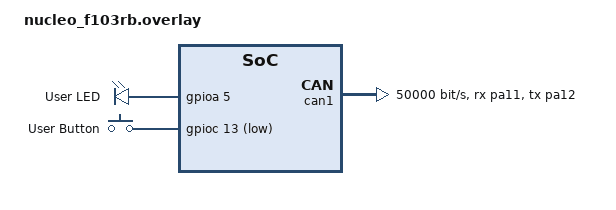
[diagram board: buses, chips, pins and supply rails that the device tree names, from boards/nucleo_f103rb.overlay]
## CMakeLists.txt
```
cmake_minimum_required(VERSION 3.20.0)

find_package(Zephyr REQUIRED HINTS $ENV{ZEPHYR_BASE})
project(antenna_app)

list(APPEND CMAKE_MODULE_PATH ${ZEPHYR_BASE}/modules/nanopb)
include(nanopb)

file(GLOB_RECURSE RADIOLIB_SOURCES
    ${CMAKE_CURRENT_SOURCE_DIR}/lib/RadioLib/src/*.cpp
)
list(FILTER RADIOLIB_SOURCES EXCLUDE REGEX ".*/hal/.*\\.cpp$")

target_sources(app PRIVATE
    src/main.cpp
    src/radio.cpp
    src/hal/radio_hal.cpp
    src/can_handler.cpp  # Add your CAN file here too
    src/metrics.cpp
    ${RADIOLIB_SOURCES}
)

target_include_directories(app PRIVATE
    ${CMAKE_CURRENT_SOURCE_DIR}/lib/RadioLib/src
    ${CMAKE_CURRENT_SOURCE_DIR}/src/hal
)

# 2. Add Nanopb sources. 
# Zephyr's Nanopb module provides this function automatically 
# if CONFIG_NANOPB=y is in your prj.conf.
zephyr_nanopb_sources(app src/dant_link.proto)
```

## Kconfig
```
mainmenu "DANT Application"

source "Kconfig.zephyr"

menu "DANT options"

choice DANT_NODE_ROLE
	prompt "DANT node role"
	default DANT_NODE_A

config DANT_NODE_A
	bool "Node A"

config DANT_NODE_B
	bool "Node B"

endchoice

config DANT_TX_PERIOD_MS
	int "TX period in milliseconds"
	default 1000
	range 10 60000

endmenu
```

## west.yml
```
manifest:
  remotes:
    - name: zephyrproject
      url-base: https://github.com/zephyrproject-rtos

  projects:
    - name: zephyr
      remote: zephyrproject
      revision: 3568e1b6d5cdd51a6b964a2a1d6d29200fea2056
      import:
        name-allowlist:
          - cmsis_6
          - hal_stm32
          - nanopb

  self:
    path: antenna_app
```

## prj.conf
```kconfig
# Kernel
CONFIG_MAIN_STACK_SIZE=2048
CONFIG_HEAP_MEM_POOL_SIZE=2048
CONFIG_REBOOT=y

# Console
CONFIG_SERIAL=y
CONFIG_CONSOLE=y
CONFIG_PRINTK=y

# GPIO
CONFIG_GPIO=y
# This enables the specific STM32F1xx HAL driver files

# SPI
CONFIG_SPI=y

# CAN
CONFIG_CAN=y
## STM32 requires specific clock settings for CAN, usually handled by Zephyr
CONFIG_STATS=y
CONFIG_CAN_STATS=y

# Debugger
CONFIG_DEBUG=y
CONFIG_DEBUG_OPTIMIZATIONS=y

# Logger
CONFIG_LOG=y
CONFIG_LOG_DEFAULT_LEVEL=3

# C++
CONFIG_CPP=y

CONFIG_STDOUT_CONSOLE=y
CONFIG_UART_CONSOLE=y

# Enable protobuf
CONFIG_NANOPB=y
```

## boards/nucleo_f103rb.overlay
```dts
/ {
    chosen {
        /* Links the CAN driver to your code's DEVICE_DT_GET(DT_CHOSEN(zephyr_canbus)) */
        zephyr,canbus = &can1;
    };

    /* Most STM32F103 boards already have 'led0' defined in the base DTS,
       but we ensure the alias is set here for the blinky code. */
    aliases {
        led0 = &green_led_1;
		/* Define the sw0 alias so your code can find the button */
        sw0 = &user_button_1;
    };

    leds {
        compatible = "gpio-leds";
        green_led_1: led_1 {
            gpios = <&gpioa 5 GPIO_ACTIVE_HIGH>;
            label = "User LED";
        };
    };

	/* Add the buttons node here */
    buttons {
        compatible = "gpio-keys";
        user_button_1: button_1 {
            /* PC13 is the standard B1 button on the Nucleo-F103RB */
            gpios = <&gpioc 13 GPIO_ACTIVE_LOW>;
            label = "User Button";
        };
    };
};

/* CAN configuration */
&can1 {
    status = "okay";
    pinctrl-0 = <&can_rx_pa11 &can_tx_pa12>;
    pinctrl-names = "default";
    bitrate = <50000>;
    sample-point = <750>;

    /* Optional: If you have a transceiver with a standby pin */
    /* standby-gpios = <&gpiob 0 GPIO_ACTIVE_HIGH>; */
};
```

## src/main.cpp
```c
#include <zephyr/kernel.h>
#include <zephyr/sys/printk.h>
#include <zephyr/drivers/gpio.h>
#include <zephyr/logging/log.h>
#include <zephyr/sys/reboot.h>
//#include <state_system.h>
#include <RadioLib.h>
#include <STMRadioHal.h>
#include <zephyr/drivers/spi.h>
#include <string.h>
#include "radio.h"


#define SPI_DEV    DT_NODELABEL(spi1)
#define GPIO_NODE  DT_NODELABEL(gpioa)
#define GPIO_CS_NODE DT_NODELABEL(gpioa)
#define CS_PIN     4
#define IRQ_PIN    8
#define RST_PIN    9
#define BUSY_PIN   10
#define RADIO_TASK_STACK_SIZE 4096
#define RADIO_TASK_PRIORITY 5

enum class State {
    BOOT,
    WAKE,
    DEPLOYING,
    VITALS,
    REGULAR,
    FAULT,
    RESTART,
    SAFE,
    RADIO_TEST
};

LOG_MODULE_REGISTER(radio_task, CONFIG_LOG_DEFAULT_LEVEL);

const struct device *const spi_bus = DEVICE_DT_GET(SPI_DEV);
const struct device *const gpio_port = DEVICE_DT_GET(GPIO_NODE);
const struct device *const gpio_cs_port = DEVICE_DT_GET(GPIO_CS_NODE);


K_THREAD_STACK_DEFINE(radio_task_stack, RADIO_TASK_STACK_SIZE);
//static struct k_thread radio_task_thread;
static bool radio_thread_started = false;

volatile bool tx_done = false;
State currentState = State::BOOT;

void onTxDone(void)
{
    tx_done = true;
}

static void radio_queue_entry(void *p1, void *p2, void *p3)
{
    ARG_UNUSED(p1);
    ARG_UNUSED(p2);
    ARG_UNUSED(p3);
    radio_task_cpp();
}

/*
static bool start_radio_thread_once(void)
{
    if (radio_thread_started) {
        return true;
    }

    k_thread_create(
        &radio_task_thread,
        radio_task_stack,
        K_THREAD_STACK_SIZEOF(radio_task_stack),
        radio_queue_entry,
        NULL,
        NULL,
        NULL,
        RADIO_TASK_PRIORITY,
        0,
        K_NO_WAIT);

    radio_thread_started = true;
    return true;
}
*/
int main(void)
{
    while (1) {
        if(fault_take){//execute when it fault_take() return true
            LOG_ERR("Fault flag: FAULT");
            currentState = State :: FAULT; //set the state to FAULT
        }
        switch (currentState) {
        case State::BOOT: {
            bool ready = true;

            if (!check_spi(spi_bus)) {
                LOG_ERR("SPI bus not ready");
                ready = false;
            }

            if (!check_gpio(gpio_port)) {
                check_gpio();
                LOG_ERR("GPIO port not ready");
                ready = false;
            }

            if (!check_gpio_cs(gpio_cs_port)) {
                LOG_ERR("GPIO CS port not ready");
                ready = false;
            }

            if (!ready) {
                currentState = State::FAULT;
                break;
            }

            if (check_init_radio() != 0) {
                LOG_ERR("Radio init failed");
                currentState = State::FAULT;
                break;
            }

            if (!start_radio_thread_once()) {
                LOG_ERR("Radio thread start failed");
                currentState = State::FAULT;
                break;
            }

            currentState = State::WAKE;
            break;
        }

        case State::WAKE:
            LOG_INF("State: WAKE");
            currentState = State::VITALS;
            break;

        case State::DEPLOYING:
            LOG_INF("State: DEPLOYING");
            currentState = State::REGULAR;
            break;

        case State::VITALS:
            LOG_INF("State: VITALS");
            currentState = State::REGULAR;
            break;

        case State::REGULAR:
            // Normal operations placeholder.
            k_msleep(100);
            break;

        case State::SAFE:
            LOG_WRN("State: SAFE");
            k_msleep(250);
            break;

        case State::RADIO_TEST:
            LOG_INF("State: RADIO_TEST");
            radio_test();
            currentState = State::REGULAR;
            break;

        case State::FAULT:
            LOG_ERR("State: FAULT");
            currentState = State::RESTART;
            break;

        case State::RESTART:
            LOG_WRN("State: RESTART");
            k_msleep(100);
            sys_reboot(SYS_REBOOT_COLD); // this is powering off and restarting, not just rebooting
            break;
        }
    }

    return 0;
}
```

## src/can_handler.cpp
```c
#include <zephyr/device.h>
#include <zephyr/drivers/can.h>
#include <zephyr/kernel.h>
#include <zephyr/sys/printk.h>

CAN_MSGQ_DEFINE(can_rx_queue, 4);

static void print_can_state(const struct device *dev)
{
    enum can_state state;
    struct can_bus_err_cnt errors;
    const int ret = can_get_state(dev, &state, &errors);

    if (ret == 0) {
        printk("CAN state=%d tx_errors=%u rx_errors=%u\n",
               (int)state, errors.tx_err_cnt, errors.rx_err_cnt);
    }
}

static void can_task_entry(void *arg1, void *arg2, void *arg3)
{
    ARG_UNUSED(arg1);
    ARG_UNUSED(arg2);
    ARG_UNUSED(arg3);

    const struct device *const can_dev =
        DEVICE_DT_GET(DT_CHOSEN(zephyr_canbus));

    if (!device_is_ready(can_dev)) {
        printk("CAN device is not ready\n");
        return;
    }

    int ret = can_set_mode(can_dev, CAN_MODE_NORMAL);
    if (ret != 0) {
        printk("CAN mode failed: %d\n", ret);
        return;
    }

    const struct can_filter filter = {
        .id = 0x123,
        .mask = CAN_STD_ID_MASK,
        .flags = 0U,
    };
    const int filter_id = can_add_rx_filter_msgq(
        can_dev, &can_rx_queue, &filter);
    if (filter_id < 0) {
        printk("CAN filter registration failed: %d\n", filter_id);
        return;
    }

    printk("Node %s: RX filter installed for ID 0x123\n",
           IS_ENABLED(CONFIG_DANT_NODE_A) ? "A" : "B");

    ret = can_start(can_dev);
    if (ret != 0) {
        printk("CAN start failed: %d\n", ret);
        return;
    }

    printk("CAN started\n");

    struct can_frame frame = {};

    if (IS_ENABLED(CONFIG_DANT_NODE_A)) {
        frame.id = 0x123;
        frame.dlc = 1;
        frame.data[0] = 42;

        while (true) {
            printk("CAN task alive\n");
            ret = can_send(can_dev, &frame, K_MSEC(100), nullptr, nullptr);
            if (ret != 0) {
                printk("CAN send failed: %d\n", ret);
                print_can_state(can_dev);
            } else {
                printk("CAN frame sent\n");
            }
            k_msleep(1000);
        }
    } else {
        while (true) {
            ret = k_msgq_get(&can_rx_queue, &frame, K_FOREVER);
            if (ret == 0 && frame.dlc >= 1U &&
                (frame.flags & CAN_FRAME_RTR) == 0U) {
                printk("Received ID: 0x%x, data: %u\n",
                       (unsigned int)frame.id,
                       (unsigned int)frame.data[0]);
            }
        }
    }
}

K_THREAD_DEFINE(can_task_id, 1024, can_task_entry,
                nullptr, nullptr, nullptr,
                5, 0, 0);
```

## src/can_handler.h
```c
#ifndef CAN_HANDLER_H
#define CAN_HANDLER_H

#include <zephyr/types.h>

#ifdef __cplusplus
/* Add this so main.cpp can see the semaphore */
extern struct k_sem blink_sem;
extern "C" {
#endif

/**
 * @brief Initializes the CAN controller and GPIO LED.
 * * Sets up the default RX filter to accept all standard data frames,
 * configures the onboard LED for activity toggling, and starts the
 * CAN peripheral.
 *
 * @retval 0 if successful.
 * @retval -ENODEV if hardware devices are not ready.
 * @retval Negative errno code from zephyr CAN API on failure.
 */
int can_handler_init(void);

/**
 * @brief Transmits a classic CAN frame.
 *
 * @param id   The CAN ID (Standard).
 * @param data Pointer to the data buffer (max 8 bytes).
 * @param len  Length of data to send (clipped to 8).
 *
 * @retval 0 if successful.
 * @retval Negative errno code (e.g., -EAGAIN, -ENETDOWN) on failure.
 */
int can_handler_send(uint32_t id, uint8_t *data, uint8_t len);

#ifdef __cplusplus
}
#endif

#endif /* CAN_HANDLER_H */
```

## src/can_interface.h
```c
#pragma once

#include "can_link.h"
#include <cstddef>
#include <cstdint>

using CanReceiveCallback = can_link_rx_handler_t;

inline int can_interface_init(
    CanReceiveCallback callback,
    void* user_data = nullptr)
{
    return can_link_init(callback, user_data);
}

// Returns 0 when the transfer starts, not when delivery completes.
// Returns -EBUSY if another transfer is already active.
inline int can_interface_send_to(
    std::uint8_t target_node,
    const std::uint8_t* payload,
    std::size_t length)
{
    return can_link_send_to(target_node, payload, length);
}

// The current SDSL-CAN implementation limits broadcasts to 7 bytes.
inline int can_interface_send_broadcast(
    const std::uint8_t* payload,
    std::size_t length)
{
    return can_link_send_broadcast(payload, length);
}
```

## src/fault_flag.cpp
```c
#include "fault_flag.h"

static volatile bool pending = false;

void fault_request(){
    pending = true;
}

bool fault_take(){
    if(!pending){
        return false;
    }
    pending = false;
    return true;

}
```

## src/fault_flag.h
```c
#pragma once

void fault_request(void);
bool fault_take(void);
```

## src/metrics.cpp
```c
/**
 * @file metrics.cpp
 * @brief Metrics counter storage and update routines.
 *
 * Runtime counters are stored as Zephyr atomics so they can be updated from
 * the main thread, radio task, or callback paths. The boot counter is mirrored
 * in RAM but persisted through the Zephyr Settings API using the NVS backend.
 */

#include "metrics.h"

#include <errno.h>
#include <stddef.h>
#include <sys/types.h>
#include <zephyr/settings/settings.h>
#include <zephyr/sys/atomic.h>

#define METRICS_BOOT_COUNT_KEY "metrics/boot_count"

static atomic_t boot_count;
static atomic_t fault_count;
static atomic_t radio_tx_attempts;
static atomic_t radio_tx_successes;
static atomic_t radio_tx_failures;
static atomic_t radio_retries;
static atomic_t radio_queue_full_count;
static atomic_t successful_cycles;

static bool persistent_metrics_ready;

/**
 * @brief Convert a Zephyr atomic counter to the public 32-bit metric type.
 *
 * @param counter Atomic counter to read.
 * @return Current counter value.
 */
static uint32_t metrics_counter_get(const atomic_t *counter)
{
    return (uint32_t)atomic_get(counter);
}

/**
 * @brief Load the persisted boot count from Settings/NVS.
 *
 * A missing key is treated as a first boot and returns zero.
 *
 * @param value Output location for the loaded boot count.
 * @retval 0 if a value was loaded or the key did not exist.
 * @retval -EINVAL if the stored value length is unexpected.
 * @retval negative Zephyr error code from settings_load_one().
 */
static int metrics_load_boot_count(uint32_t *value)
{
    ssize_t ret = settings_load_one(METRICS_BOOT_COUNT_KEY, value, sizeof(*value));

    if (ret == -ENOENT) {
        *value = 0U;
        return 0;
    }

    if (ret < 0) {
        return (int)ret;
    }

    return ret == sizeof(*value) ? 0 : -EINVAL;
}

/**
 * @brief Persist a boot count value to Settings/NVS.
 *
 * @param value Boot count to save.
 * @retval 0 on success.
 * @retval negative Zephyr error code from settings_save_one().
 */
static int metrics_save_boot_count(uint32_t value)
{
    return settings_save_one(METRICS_BOOT_COUNT_KEY, &value, sizeof(value));
}

void metrics_init(void)
{
    uint32_t stored_boot_count = 0U;
    int ret = settings_subsys_init();

    if (ret != 0) {
        persistent_metrics_ready = false;
        atomic_inc(&fault_count);
        return;
    }

    persistent_metrics_ready = true;

    ret = metrics_load_boot_count(&stored_boot_count);
    if (ret != 0) {
        atomic_inc(&fault_count);
        return;
    }

    atomic_set(&boot_count, (atomic_val_t)stored_boot_count);
}

void metrics_inc_boot(void)
{
    uint32_t value = (uint32_t)atomic_inc(&boot_count) + 1U;

    if (persistent_metrics_ready && metrics_save_boot_count(value) != 0) {
        atomic_inc(&fault_count);
    }
}

int metrics_reset_boot_count(void)
{
    uint32_t value = 0U;

    if (!persistent_metrics_ready) {
        return -EIO;
    }

    int ret = metrics_save_boot_count(value);
    if (ret != 0) {
        return ret;
    }

    atomic_set(&boot_count, (atomic_val_t)value);
    return 0;
}

void metrics_inc_fault(void)
{
    atomic_inc(&fault_count);
}

void metrics_inc_radio_tx_attempt(void)
{
    atomic_inc(&radio_tx_attempts);
}

void metrics_inc_radio_tx_success(void)
{
    atomic_inc(&radio_tx_successes);
}

void metrics_inc_radio_tx_failure(void)
{
    atomic_inc(&radio_tx_failures);
}

void metrics_inc_radio_retry(void)
{
    atomic_inc(&radio_retries);
}

void metrics_inc_radio_queue_full(void)
{
    atomic_inc(&radio_queue_full_count);
}

void metrics_inc_successful_cycle(void)
{
    atomic_inc(&successful_cycles);
}

struct metrics_snapshot metrics_get_snapshot(void)
{
    struct metrics_snapshot snapshot = {};

    snapshot.boot_count = metrics_counter_get(&boot_count);
    snapshot.fault_count = metrics_counter_get(&fault_count);
    snapshot.radio_tx_attempts = metrics_counter_get(&radio_tx_attempts);
    snapshot.radio_tx_successes = metrics_counter_get(&radio_tx_successes);
    snapshot.radio_tx_failures = metrics_counter_get(&radio_tx_failures);
    snapshot.radio_retries = metrics_counter_get(&radio_retries);
    snapshot.radio_queue_full_count = metrics_counter_get(&radio_queue_full_count);
    snapshot.successful_cycles = metrics_counter_get(&successful_cycles);

    return snapshot;
}
```

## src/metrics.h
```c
/**
 * @file metrics.h
 * @brief Runtime and persistent health metrics for the antenna application.
 *
 * The metrics module tracks core health counters that can be sampled by
 * telemetry, debug commands, or future CAN/protobuf status messages. Most
 * counters are runtime-only atomics. The boot counter is backed by Zephyr
 * Settings/NVS so it survives reboot and power loss.
 */

#ifndef METRICS_H
#define METRICS_H

#include <stdint.h>

#ifdef __cplusplus
extern "C" {
#endif

/**
 * @brief Snapshot of all metrics counters.
 *
 * A snapshot is a point-in-time copy. It does not lock future updates, so use
 * it as telemetry/debug state rather than as a transactional record.
 */
struct metrics_snapshot {
    /** Number of completed boot-count increments persisted in Settings/NVS. */
    uint32_t boot_count;
    /** Count of recoverable fault/error paths observed since this boot. */
    uint32_t fault_count;
    /** Number of radio transmit operations attempted since this boot. */
    uint32_t radio_tx_attempts;
    /** Number of radio transmit operations that completed successfully. */
    uint32_t radio_tx_successes;
    /** Number of radio transmit operations that failed after retries. */
    uint32_t radio_tx_failures;
    /** Number of additional radio transmit attempts after first failure. */
    uint32_t radio_retries;
    /** Number of radio queue insertions rejected because the queue was full. */
    uint32_t radio_queue_full_count;
    /** Number of application cycles that reached a successful TX completion. */
    uint32_t successful_cycles;
};

/**
 * @brief Initialize metrics storage and load persistent counters.
 *
 * This initializes the Zephyr Settings backend and loads the persisted
 * `boot_count`. If persistent storage cannot be initialized or read, the
 * module keeps running with runtime counters and records a fault.
 */
void metrics_init(void);

/**
 * @brief Increment and persist the boot counter.
 *
 * Call once during application startup after metrics_init(). The saved value is
 * updated immediately so the count survives a later reset or power loss.
 */
void metrics_inc_boot(void);

/**
 * @brief Reset the persistent and in-memory boot count to zero.
 *
 * The next startup call to metrics_inc_boot() will report boot_count == 1.
 *
 * @retval 0 if the reset was saved and applied.
 * @retval -EIO if persistent metrics storage is not ready.
 * @retval negative Zephyr error code if Settings/NVS could not save the value.
 */
int metrics_reset_boot_count(void);

/** @brief Increment the recoverable fault counter. */
void metrics_inc_fault(void);

/** @brief Increment the radio transmit attempt counter. */
void metrics_inc_radio_tx_attempt(void);

/** @brief Increment the radio transmit success counter. */
void metrics_inc_radio_tx_success(void);

/** @brief Increment the radio transmit failure counter. */
void metrics_inc_radio_tx_failure(void);

/** @brief Increment the radio retry counter. */
void metrics_inc_radio_retry(void);

/** @brief Increment the radio queue-full counter. */
void metrics_inc_radio_queue_full(void);

/** @brief Increment the successful application cycle counter. */
void metrics_inc_successful_cycle(void);

/**
 * @brief Return a point-in-time copy of all metrics counters.
 *
 * @return Snapshot containing persistent boot count and runtime counters.
 */
struct metrics_snapshot metrics_get_snapshot(void);

#ifdef __cplusplus
}
#endif

#endif /* METRICS_H */
```

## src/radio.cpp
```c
#include "radio.h"
#include "hal/STMRadioHal.h"
#include <zephyr/drivers/gpio.h>
#include <zephyr/drivers/spi.h>
#include <zephyr/logging/log.h>
#include <string.h>

LOG_MODULE_REGISTER(radio, CONFIG_LOG_DEFAULT_LEVEL);

extern "C" __attribute__((weak)) void telemetry_send_radio_stats(int16_t rssi, int8_t snr, uint8_t radio) {
    ARG_UNUSED(rssi);
    ARG_UNUSED(snr);
    ARG_UNUSED(radio);
}

// Radio instances
static Module* module_sx = nullptr;
static Module* module_rfm = nullptr;
static SX1268* radio_sx = nullptr;
static RFM98* radio_rfm = nullptr;
static STMRadioHal* hal_sx = nullptr;
static STMRadioHal* hal_rfm = nullptr;

// Current active radio state
static uint8_t current_radio = 0; // 0 = SX1268, 1 = RFM98
static bool sx_initialized = false;
static bool rfm_initialized = false;

// State tracking
static int16_t rfm_state = RADIOLIB_ERR_NONE;
static int16_t sx_state = RADIOLIB_ERR_NONE;

// Message queue for radio operations
K_MSGQ_DEFINE(radio_msgq, sizeof(radio_queue_operations_t), RADIO_MAX_QUEUE_ITEMS, 4);

// Device pointers (to be initialized)
static const struct device* gpio_ports[] = {nullptr, nullptr};
static const struct device* spi_dev = nullptr;

// Forward declarations
static void configure_radio_pins();
static void set_rf_switch(uint8_t radio);
static int16_t transmit_packet(uint8_t* data, size_t size);
static int16_t get_packet_stats(int16_t* rssi, int8_t* snr);
static const struct device* radio_gpio_device(uint32_t encoded_pin);
static gpio_pin_t radio_gpio_pin(uint32_t encoded_pin);
static void radio_gpio_configure(uint32_t encoded_pin, gpio_flags_t flags);
static void radio_gpio_set(uint32_t encoded_pin, int value);

static int init_radio() {
    // Get GPIO and SPI devices from device tree
    gpio_ports[RADIO_GPIO_PORT_A] = DEVICE_DT_GET(DT_NODELABEL(gpioa));
    gpio_ports[RADIO_GPIO_PORT_B] = DEVICE_DT_GET(DT_NODELABEL(gpiob));
    if (!device_is_ready(gpio_ports[RADIO_GPIO_PORT_A]) || !device_is_ready(gpio_ports[RADIO_GPIO_PORT_B])) {
        LOG_ERR("GPIO devices not ready");
        return -1;
    }

    spi_dev = DEVICE_DT_GET(DT_NODELABEL(spi1));
    if (!device_is_ready(spi_dev)) {
        LOG_ERR("SPI device not ready");
        return -1;
    }

    // Initialize HAL instances
    hal_sx = new STMRadioHal(spi_dev, gpio_ports[RADIO_GPIO_PORT_A], 2000000);
    hal_rfm = new STMRadioHal(spi_dev, gpio_ports[RADIO_GPIO_PORT_A], 2000000);

    // Configure radio pins
    configure_radio_pins();

    // Initialize SX1268 radio
    set_rf_switch(0);
    k_msleep(10);
    module_sx = new Module(hal_sx, RADIO_SX_NSS_PIN, RADIO_SX_DIO1_PIN, RADIO_SX_NRST_PIN, RADIO_SX_BUSY_PIN);
    radio_sx = new SX1268(module_sx);
    sx_state = radio_sx->begin(
        RADIO_FREQ,
        RADIO_BW,
        RADIO_SF,
        RADIO_CR,
        RADIO_SYNC_WORD,
        10,
        RADIO_PREAMBLE_LEN,
        RADIO_SX_TXCO_VOLT,
        RADIO_SX_USE_REG_LDO
    );
    if (sx_state == RADIOLIB_ERR_NONE) {
        sx_initialized = true;
        LOG_INF("SX1268 initialized successfully");
    } else {
        LOG_ERR("SX1268 initialization failed: %d", sx_state);
    }

    // RFM98 init intentionally skipped for SX-only operation.
    rfm_initialized = false;

    // Set default configuration
    if (sx_initialized) {
        radio_sx->setFrequency(RADIO_FREQ);
        radio_sx->setBandwidth(RADIO_BW);
        radio_sx->setSpreadingFactor(RADIO_SF);
        radio_sx->setCodingRate(RADIO_CR);
        radio_sx->setSyncWord(RADIO_SYNC_WORD);
        radio_sx->setPreambleLength(RADIO_PREAMBLE_LEN);
    }

    LOG_INF("Radio initialization complete");

    return 0;
}

static const struct device* radio_gpio_device(uint32_t encoded_pin) {
    uint32_t port = RADIO_GPIO_PORT(encoded_pin);
    return (port < ARRAY_SIZE(gpio_ports)) ? gpio_ports[port] : nullptr;
}

static gpio_pin_t radio_gpio_pin(uint32_t encoded_pin) {
    return (gpio_pin_t)RADIO_GPIO_PIN(encoded_pin);
}

static void radio_gpio_configure(uint32_t encoded_pin, gpio_flags_t flags) {
    const struct device* gpio_dev = radio_gpio_device(encoded_pin);
    if (gpio_dev != nullptr) {
        gpio_pin_configure(gpio_dev, radio_gpio_pin(encoded_pin), flags);
    }
}

static void radio_gpio_set(uint32_t encoded_pin, int value) {
    const struct device* gpio_dev = radio_gpio_device(encoded_pin);
    if (gpio_dev != nullptr) {
        gpio_pin_set(gpio_dev, radio_gpio_pin(encoded_pin), value);
    }
}

static void configure_radio_pins() {
    // Configure NSS pins as output
    radio_gpio_configure(RADIO_SX_NSS_PIN, GPIO_OUTPUT);
    radio_gpio_configure(RADIO_RFM_NSS_PIN, GPIO_OUTPUT);

    // Configure RF switch control pin
    radio_gpio_configure(RADIO_RF_SWITCH_PIN, GPIO_OUTPUT);

    // Set initial states
    radio_gpio_set(RADIO_SX_NSS_PIN, 1);
    radio_gpio_set(RADIO_RFM_NSS_PIN, 1);
}

static void set_rf_switch(uint8_t radio) {
    radio_gpio_set(RADIO_RF_SWITCH_PIN, radio == 0 ? RADIO_RF_SWITCH_SX : RADIO_RF_SWITCH_RFM);
}

void radio_task_cpp() {
    radio_queue_operations_t op;

    while (1) {
        // Wait for operation from queue
        k_msgq_get(&radio_msgq, &op, K_FOREVER);

        switch (op.operation_type) {
            case TRANSMIT:
                if (current_radio == 0 && sx_initialized) {
                    set_rf_switch(0);
                    sx_state = transmit_packet(op.data_buffer, op.data_size);
                } else if (current_radio == 1 && rfm_initialized) {
                    set_rf_switch(1);
                    rfm_state = transmit_packet(op.data_buffer, op.data_size);
                }
                break;

            case SET_OUTPUT_POWER:
                if (current_radio == 0 && sx_initialized) {
                    sx_state = radio_sx->setOutputPower(op.data_size); // data_size used as power value
                } else if (current_radio == 1 && rfm_initialized) {
                    // RFM98 has +14dBm offset
                    rfm_state = radio_rfm->setOutputPower(op.data_size - 14);
                }
                break;

            case ENABLE_RFM98:
                if (rfm_initialized) {
                    current_radio = 1;
                    set_rf_switch(1);
                    LOG_INF("Switched to RFM98 radio");
                }
                break;

            case ENABLE_SX1268:
                if (sx_initialized) {
                    current_radio = 0;
                    set_rf_switch(0);
                    LOG_INF("Switched to SX1268 radio");
                }
                break;

            case RETURN_STATS:
                {
                    int16_t rssi = 0;
                    int8_t snr = 0;
                    if (current_radio == 0 && sx_initialized) {
                        sx_state = get_packet_stats(&rssi, &snr);
                        if (sx_state == RADIOLIB_ERR_NONE) {
                            telemetry_send_radio_stats(rssi, snr, 0);
                        }
                    } else if (current_radio == 1 && rfm_initialized) {
                        rfm_state = get_packet_stats(&rssi, &snr);
                        if (rfm_state == RADIOLIB_ERR_NONE) {
                            telemetry_send_radio_stats(rssi, snr, 1);
                        }
                    }
                }
                break;

            default:
                LOG_WRN("Unknown operation type: %d", op.operation_type);
                break;
        }

        // Free data buffer if allocated
        if (op.data_buffer != nullptr) {
            k_free(op.data_buffer);
        }
    }
}

void radio_task(void *unused_arg) {
    ARG_UNUSED(unused_arg);
    init_radio();
    radio_task_cpp();
}

static int16_t transmit_packet(uint8_t* data, size_t size) {
    if (current_radio == 0) {
        return radio_sx->transmit(data, size);
    } else {
        return radio_rfm->transmit(data, size);
    }
}

static int16_t get_packet_stats(int16_t* rssi, int8_t* snr) {
    if (current_radio == 0) {
        *rssi = radio_sx->getRSSI();
        *snr = radio_sx->getSNR();
        return RADIOLIB_ERR_NONE;
    } else {
        *rssi = radio_rfm->getRSSI();
        *snr = radio_rfm->getSNR();
        return RADIOLIB_ERR_NONE;
    }
}

void radio_queue_message(char *buffer, size_t size) {
    radio_queue_operations_t op;
    op.operation_type = TRANSMIT;
    op.data_buffer = (uint8_t*)k_malloc(size);
    if (op.data_buffer == nullptr) {
        LOG_ERR("Failed to allocate memory for radio message");
        return;
    }
    memcpy(op.data_buffer, buffer, size);
    op.data_size = size;

    k_msgq_put(&radio_msgq, &op, K_NO_WAIT);
}

void radio_set_transmit_power(uint8_t output_power) {
    radio_queue_operations_t op;
    op.operation_type = SET_OUTPUT_POWER;
    op.data_buffer = nullptr;
    op.data_size = output_power; // Reusing data_size field for power value

    k_msgq_put(&radio_msgq, &op, K_NO_WAIT);
}

void radio_set_module(radio_operation_type_t op) {
    radio_queue_operations_t queue_op;
    queue_op.operation_type = op;
    queue_op.data_buffer = nullptr;
    queue_op.data_size = 0;

    k_msgq_put(&radio_msgq, &queue_op, K_NO_WAIT);
}

void radio_queue_stat_response() {
    radio_queue_operations_t op;
    op.operation_type = RETURN_STATS;
    op.data_buffer = nullptr;
    op.data_size = 0;

    k_msgq_put(&radio_msgq, &op, K_NO_WAIT);
}

uint8_t radio_which() {
    return current_radio;
}

int16_t radio_get_RFM_state() {
    return rfm_state;
}

int16_t radio_get_SX_state() {
    return sx_state;
}

void radio_test() {
    static uint32_t test_counter = 0;
    char msg[64];

    if (!sx_initialized && !rfm_initialized) {
        init_radio();
    }

    if (!sx_initialized) {
        LOG_ERR("radio_test: SX1268 not initialized (state=%d)", sx_state);
        return;
    }

    current_radio = 0;
    set_rf_switch(0);
    LOG_INF("Starting radio_test (queue spam)");

    while (1) {
        int len = snprintf(msg, sizeof(msg), "radio_test #%lu", (unsigned long)test_counter++);
        if (len <= 0) {
            LOG_ERR("radio_test snprintf failed");
            k_msleep(1000);
            continue;
        }

        radio_queue_message(msg, (size_t)len);

        if ((test_counter % 10U) == 0U) {
            LOG_INF("Queued %lu radio_test messages", (unsigned long)test_counter);
        } else {
            LOG_DBG("Queued message: %s", msg);
        }

        if (k_msgq_num_free_get(&radio_msgq) == 0) {
            LOG_WRN("radio queue full");
            k_msleep(2000);
        } else {
            k_msleep(250);
        }
    }
}
```

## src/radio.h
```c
#pragma once

#include <zephyr/kernel.h>
#include <zephyr/sys/util.h>
#include <stdint.h>

// TODO: verify these constants
#define RADIO_SX_NSS_PIN 4
#define RADIO_SX_DIO1_PIN 8
#define RADIO_SX_NRST_PIN 9
#define RADIO_SX_BUSY_PIN 10

#define RADIO_RFM_NSS_PIN 17
#define RADIO_RFM_DIO0_PIN 27
#define RADIO_RFM_NRST_PIN 20
#define RADIO_RFM_DIO1_PIN 29

#define RADIO_FREQ 434.0
#define RADIO_BW 125.0
#define RADIO_SF 9
#define RADIO_CR 7
#define RADIO_SYNC_WORD 18
#define RADIO_PREAMBLE_LEN 8
#define RADIO_RFM_GAIN 0
#define RADIO_SX_TXCO_VOLT 0.0
#define RADIO_SX_USE_REG_LDO false

#define RADIO_MAX_QUEUE_ITEMS 64

#define RADIO_RF_SWITCH_PIN 12
#define RADIO_SX_POWER_PIN 7
#define RADIO_RFM_POWER_PIN 14

#define RADIO_RF_SWITCH_RFM 1
#define RADIO_RF_SWITCH_SX 0


extern struct k_msgq radio_msgq;

/// @brief Radio operation types for use in radio_queue_operations_t in the radio_queue
typedef enum radio_operation_type {
    TRANSMIT,
    SET_OUTPUT_POWER,
    ENABLE_RFM98,
    ENABLE_SX1268,
    RETURN_STATS,
} radio_operation_type_t;

/// @brief Radio operation to be added to the radio_queue
typedef struct radio_queue_operations {
    radio_operation_type_t operation_type; ///< What operation does, could be transmit, set power, etc
    uint8_t* data_buffer; ///< If extra data is needed for this operation, for example if the operation is transmit then the data will be the buffer to transmit
    size_t data_size; ///< Could be 0
} radio_queue_operations_t;

#ifdef __cplusplus
extern "C" {
    // #include "telemetry.h"
    // #include "log.h"
    // #include "command.h"
}
#endif
#ifdef __cplusplus
extern "C"
{
#endif
    /**
     * @brief C Linkage for radio task function (cpp version is radio_task_cpp()) 
     * 
     * @param unused_arg 
     */
    void radio_task(void *unused_arg);

    /**
     * @brief Adds a message to the radio queue to be transmitted
     * 
     * @param buffer Message to transmit 
     * @param size Size of the message in bytes 
     */
    void radio_queue_message(char *buffer, size_t size);

    /**
     * @brief Changes the transmit power used by the radios
     * The RFM98PW includes and offset of +14dBm to what it is set at
     * so this function will subtract 14 from the given parameter to 
     * accurately produce the output power. This increases the minimum allowed 
     * dBm by 14 as well 
     * 
     * @param output_power New output power in dB
     */
    void radio_set_transmit_power(uint8_t output_power);
    
    /**
     * @brief Adds a change radio module being used operation to the radio queue 
     * 
     * @param op radio_queue_operations_t with operation_type of ENABLE_RFM98 or ENABLE_SX1268
     */
    void radio_set_module(radio_operation_type_t op);
    
    /**
     * @brief Adds a stat response operation to the radio queue
     * Stats Response Operation sends a packet of RSSI, SNR, and Frequency Error
     * 
     */
    void radio_queue_stat_response(); 

    /**
     * @brief Returns which radio is currently set to be used 
     * 
     * @return uint8_t 1 if radio is RFM98, 0 if radio is SX1268
     */
    uint8_t radio_which(); 

    /**
     * @brief Returns the last recorded state from a function called on the RFM98 radio 
     * 
     * @return int16_t RadioLib error code
     */
    int16_t radio_get_RFM_state();
    
    /**
     * @brief Returns the last recorded state from a function called on the SX1268 radio
     * 
     * @return int16_t 
     */
    int16_t radio_get_SX_state(); 

    /**
     * @brief Test helper: initialize radio, queue spam messages, and transmit them.
     */
    void radio_test();
#ifdef __cplusplus
}
#endif

/**
 * @brief Initializes necessary peripherals/settings for the radio task
 * 
 * @retval 0 if at least one radio initializes successfully.
 * @retval Negative errno code if required devices are not ready or radio init fails.
 */
int init_radio();

/**
 * @brief The implementation of the radio task function (Linked to C by radio_task())
 * 
 */
void radio_task_cpp();
```

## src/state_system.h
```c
#include <stdint.h>
#include <zephyr/drivers/gpio.h>
#include <zephyr/drivers/spi.h>
#include <zephyr/drivers/can.h>
#include <zephyr/drivers/i2c.h>
#include <zephyr/devicetree.h>


struct device_configuration{
    const device* i2c_port;
    const device* spi_port;
    const device* gpio_port;
    const device* gpio_cs_port;
    const device* can_bus;
};

extern const struct device_configuration device_config; 
```
